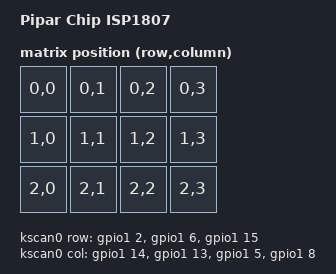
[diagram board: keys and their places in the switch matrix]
/dts-v1/;
#include <nordic/nrf52840_qiaa.dtsi>

#include <dt-bindings/led/led.h>
#include <dt-bindings/zmk/matrix_transform.h>

#include "pipar_chip_isp1807-pinctrl.dtsi"
#include "pipar_chip_isp1807-layouts.dtsi"

&physical_layout0 {
    transform = <&matrix_transform0>;
};

/ {
    model = "Pipar Chip ISP1807";
    compatible = "pipar_chip_isp1807";

    chosen {
        zephyr,code-partition = &code_partition;
        zephyr,sram = &sram0;
        zephyr,flash = &flash0;
        zmk,kscan = &kscan0;
        zmk,physical-layout = &physical_layout0;
    };

    matrix_transform0: keymap_transform_0 {
        compatible = "zmk,matrix-transform";
        rows = <3>;
        columns = <4>;
        map = <
            RC(0, 0) RC(0, 1) RC(0, 2) RC(0, 3)
            RC(1, 0) RC(1, 1) RC(1, 2) RC(1, 3)
            RC(2, 0) RC(2, 1) RC(2, 2) RC(2, 3)
        >;
    };

    kscan0: kscan {
        compatible = "zmk,kscan-gpio-matrix";
        wakeup-source;

        diode-direction = "col2row";
        row-gpios
            = <&gpio1 2  (GPIO_ACTIVE_HIGH | GPIO_PULL_DOWN)>
            , <&gpio1 6  (GPIO_ACTIVE_HIGH | GPIO_PULL_DOWN)>
            , <&gpio1 15 (GPIO_ACTIVE_HIGH | GPIO_PULL_DOWN)>
            ;
        
        col-gpios
            = <&gpio1 14 GPIO_ACTIVE_HIGH>
            , <&gpio1 13 GPIO_ACTIVE_HIGH>
            , <&gpio1 5 GPIO_ACTIVE_HIGH>
            , <&gpio1 8 GPIO_ACTIVE_HIGH>
            ;

    };

    leds {
        compatible = "gpio-leds";
        led1: led_1 {
            gpios = <&gpio1 0 GPIO_ACTIVE_HIGH>;
            label = "LED 1";
        };

        led2: led_2 {
            gpios = <&gpio1 3 GPIO_ACTIVE_HIGH>;
            label = "LED 2";
        };

        led3: led_3 {
            gpios = <&gpio1 12 GPIO_ACTIVE_HIGH>;
            label = "LED 3";
        };
    };
};

&adc {
    status = "okay";
};

&gpiote {
    status = "okay";
};

&gpio0 {
    status = "okay";
};

&gpio1 {
    status = "okay";
};

zephyr_udc0: &usbd {
    status = "okay";
};

&flash0 {
    /*
     * For more information, see:
     * http://docs.zephyrproject.org/latest/devices/dts/flash_partitions.html
     */
    partitions {
        compatible = "fixed-partitions";
        #address-cells = <1>;
        #size-cells = <1>;

        sd_partition: partition@0 {
            reg = <0x00000000 0x00026000>;
        };
        code_partition: partition@26000 {
            reg = <0x00026000 0x000c6000>;
        };

        /*
         * The flash starting at 0x000ec000 and ending at
         * 0x000f3fff is reserved for use by the application.
         */

        /*
         * Storage partition will be used by FCB/LittleFS/NVS
         * if enabled.
         */
        storage_partition: partition@ec000 {
            reg = <0x000ec000 0x00008000>;
        };

        boot_partition: partition@f4000 {
            reg = <0x000f4000 0x0000c000>;
        };
    };
};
